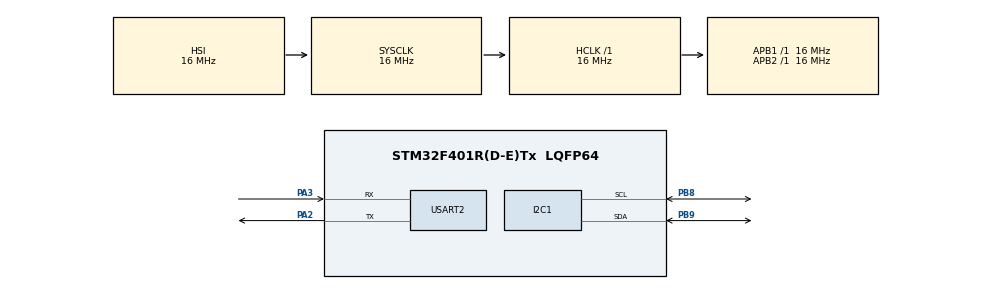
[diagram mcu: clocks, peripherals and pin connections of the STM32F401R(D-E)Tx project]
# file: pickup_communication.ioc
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I2C1.OwnAddress=0x1a
Mcu.Family=STM32F4
Mcu.Name=STM32F401R(D-E)Tx
Mcu.Package=LQFP64
NVIC.I2C1_EV_IRQn=true\:0\:0\:false\:false\:true\:true\:true
NVIC.PriorityGroup=NVIC_PRIORITYGROUP_4
NVIC.USART2_IRQn=true\:0\:0\:false\:false\:true\:true\:true
PA2.Mode=Asynchronous
PA2.Signal=USART2_TX
PA3.Mode=Asynchronous
PA3.Signal=USART2_RX
PB8.Mode=I2C
PB8.Signal=I2C1_SCL
PB9.Mode=I2C
PB9.Signal=I2C1_SDA
ProjectManager.HeapSize=0x200
ProjectManager.StackSize=0x400
ProjectManager.TargetToolchain=STM32CubeIDE
RCC.AHBFreq_Value=16000000
RCC.APB1Freq_Value=16000000
RCC.APB2Freq_Value=16000000
RCC.CortexFreq_Value=16000000
RCC.HSE_VALUE=25000000
RCC.HSI_VALUE=16000000
RCC.LSE_VALUE=32768
RCC.SYSCLKFreq_VALUE=16000000
RCC.VCOOutputFreq_Value=192000000
USART2.VirtualMode=VM_ASYNC
board=custom

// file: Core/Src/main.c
/* USER CODE BEGIN Header */
/**
  ******************************************************************************
  * @file           : main.c
  * @brief          : Main program body
  ******************************************************************************
  * @attention
  *
  * <h2><center>&copy; Copyright (c) 2020 STMicroelectronics.
  * All rights reserved.</center></h2>
  *
  * This software component is licensed by ST under BSD 3-Clause license,
  * the "License"; You may not use this file except in compliance with the
  * License. You may obtain a copy of the License at:
  *                        opensource.org/licenses/BSD-3-Clause
  *
  ******************************************************************************
  */
/* USER CODE END Header */

#include "main.h"

/* USER CODE BEGIN Includes */
#include <string.h>
#include "i2c-communication.h"
/* USER CODE END Includes */

I2C_HandleTypeDef hi2c1;

UART_HandleTypeDef huart2;

void SystemClock_Config(void);
static void MX_GPIO_Init(void);
static void MX_I2C1_Init(void);
static void MX_USART2_UART_Init(void);

int main(void)
{

  /* MCU Configuration--------------------------------------------------------*/

  /* Reset of all peripherals, Initializes the Flash interface and the Systick. */
  HAL_Init();

  /* Configure the system clock */
  SystemClock_Config();

  /* Initialize all configured peripherals */
  MX_GPIO_Init();
  MX_I2C1_Init();
  MX_USART2_UART_Init();
  /* USER CODE BEGIN 2 */
  // the following array can be used to send commands to the motors
  float position_args[5];
  uint8_t ready_message[20];
  strcpy((char*)ready_message, "device rebooted\n\r");
  HAL_UART_Transmit_IT(&huart2, ready_message, strlen((char*)ready_message));
  /* USER CODE END 2 */

  /* Infinite loop */
  while (1)
  {

    /* USER CODE BEGIN 3 */
	// HAL_Delay(500);
	receive_command(&hi2c1, position_args);
	uint8_t demo[100];
		sprintf((char*)demo, "%d %d %d %d %d\n\r", (int)(position_args[0]*2),
				(int)(position_args[1]*2),
				(int)(position_args[2]*2),
				(int)(position_args[3]*2),
				(int)(position_args[4]*2));
		HAL_UART_Transmit_IT(&huart2, demo, (uint16_t)strlen((char*)demo));
  }
  /* USER CODE END 3 */
}

void SystemClock_Config(void)
{
  RCC_OscInitTypeDef RCC_OscInitStruct = {0};
  RCC_ClkInitTypeDef RCC_ClkInitStruct = {0};

  /** Configure the main internal regulator output voltage
  */
  __HAL_RCC_PWR_CLK_ENABLE();
  __HAL_PWR_VOLTAGESCALING_CONFIG(PWR_REGULATOR_VOLTAGE_SCALE2);
  /** Initializes the CPU, AHB and APB busses clocks
  */
  RCC_OscInitStruct.OscillatorType = RCC_OSCILLATORTYPE_HSI;
  RCC_OscInitStruct.HSIState = RCC_HSI_ON;
  RCC_OscInitStruct.HSICalibrationValue = RCC_HSICALIBRATION_DEFAULT;
  RCC_OscInitStruct.PLL.PLLState = RCC_PLL_NONE;
  if (HAL_RCC_OscConfig(&RCC_OscInitStruct) != HAL_OK)
  {
    Error_Handler();
  }
  /** Initializes the CPU, AHB and APB busses clocks
  */
  RCC_ClkInitStruct.ClockType = RCC_CLOCKTYPE_HCLK|RCC_CLOCKTYPE_SYSCLK
                              |RCC_CLOCKTYPE_PCLK1|RCC_CLOCKTYPE_PCLK2;
  RCC_ClkInitStruct.SYSCLKSource = RCC_SYSCLKSOURCE_HSI;
  RCC_ClkInitStruct.AHBCLKDivider = RCC_SYSCLK_DIV1;
  RCC_ClkInitStruct.APB1CLKDivider = RCC_HCLK_DIV1;
  RCC_ClkInitStruct.APB2CLKDivider = RCC_HCLK_DIV1;

  if (HAL_RCC_ClockConfig(&RCC_ClkInitStruct, FLASH_LATENCY_0) != HAL_OK)
  {
    Error_Handler();
  }
}

static void MX_I2C1_Init(void)
{

  hi2c1.Instance = I2C1;
  hi2c1.Init.ClockSpeed = 100000;
  hi2c1.Init.DutyCycle = I2C_DUTYCYCLE_2;
  hi2c1.Init.OwnAddress1 = 52;
  hi2c1.Init.AddressingMode = I2C_ADDRESSINGMODE_7BIT;
  hi2c1.Init.DualAddressMode = I2C_DUALADDRESS_DISABLE;
  hi2c1.Init.OwnAddress2 = 0;
  hi2c1.Init.GeneralCallMode = I2C_GENERALCALL_DISABLE;
  hi2c1.Init.NoStretchMode = I2C_NOSTRETCH_DISABLE;
  if (HAL_I2C_Init(&hi2c1) != HAL_OK)
  {
    Error_Handler();
  }

}

static void MX_USART2_UART_Init(void)
{

  huart2.Instance = USART2;
  huart2.Init.BaudRate = 115200;
  huart2.Init.WordLength = UART_WORDLENGTH_8B;
  huart2.Init.StopBits = UART_STOPBITS_1;
  huart2.Init.Parity = UART_PARITY_NONE;
  huart2.Init.Mode = UART_MODE_TX_RX;
  huart2.Init.HwFlowCtl = UART_HWCONTROL_NONE;
  huart2.Init.OverSampling = UART_OVERSAMPLING_16;
  if (HAL_UART_Init(&huart2) != HAL_OK)
  {
    Error_Handler();
  }

}

static void MX_GPIO_Init(void)
{

  /* GPIO Ports Clock Enable */
  __HAL_RCC_GPIOA_CLK_ENABLE();
  __HAL_RCC_GPIOB_CLK_ENABLE();

}

void Error_Handler(void)
{
}

/************************ (C) COPYRIGHT STMicroelectronics *****END OF FILE****/
